# AT32F405 register map
Vendor: Keil; Series: AT32F405; File version: 1.0
CPU: CM4 r0p1, little endian, no MPU, FPU, 4 interrupt priority bits
Registers are 32-bit, read-write, reset 0x0 unless marked. A register's access mark holds for its fields unless they carry their own. Offsets are from the block's base; [hi:lo] are bit positions; {n}, {i} and the like mark numbered series.

## PWC — Power control
Base 0x40007000
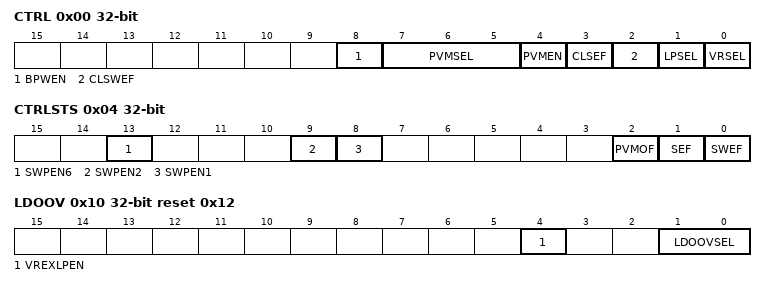
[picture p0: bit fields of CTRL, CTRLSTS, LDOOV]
0x00 CTRL — Power control register (PWC_CTRL)
  [8] BPWEN — Battery powered domain write enable
  [7:5] PVMSEL — Power voltage monitoring boundary select
  [4] PVMEN — Power voltage monitoring enable
  [3] CLSEF — Clear SEF flag
  [2] CLSWEF — Clear SWEF flag
  [1] LPSEL — Low power mode select when Cortex-M4F sleepdeep
  [0] VRSEL — Voltage regulator state select when deepsleep mode
0x04 CTRLSTS — Power control and status register (PWC_CTRLSTS)
  [13] SWPEN6 — Standby wake-up pin 6 enable
  [9] SWPEN2 — Standby wake-up pin 2 enable
  [8] SWPEN1 — Standby wake-up pin 1 enable
  [2] PVMOF ro — Power voltage monitoring output flag
  [1] SEF ro — Standby mode entry flag
  [0] SWEF ro — Standby wake-up event flag
0x10 LDOOV reset 0x12 — LDO output voltage register
  [4] VREXLPEN — Voltage regulator extra low power mode enable
  [1:0] LDOOVSEL — LDO output voltage select

## GPIOA — General purpose I/Os
Base 0x40020000
Same registers: GPIOB 0x40020400, GPIOC 0x40020800, GPIOD 0x40020C00, GPIOF 0x40021400
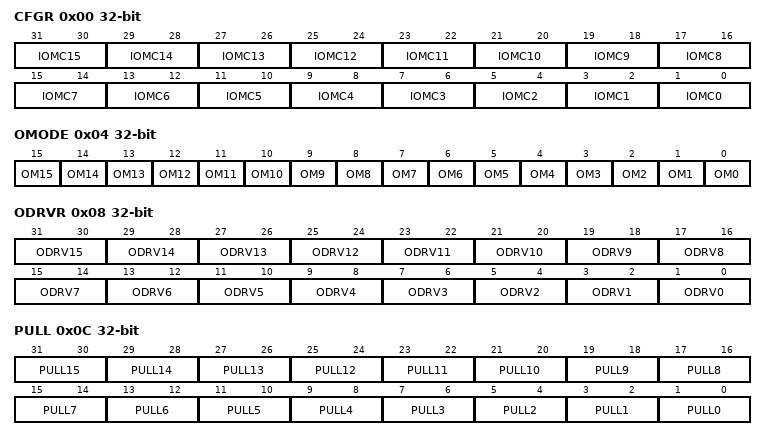
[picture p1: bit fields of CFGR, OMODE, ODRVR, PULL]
0x00 CFGR — GPIO configuration register
  [2n+1:2n] IOMC{n} (n=0..15) — GPIOx pin {n} mode configurate
    0=Input mode; 1=Output (General-purpose output mode); 2=Multiplexed function mode; 3=Analog mode
0x04 OMODE — GPIO output mode register
  [n] OM{n} (n=0..15) — GPIOx pin {n} outpu mode configurate
    0=PushPull; 1=OpenDrain
0x08 ODRVR — GPIO drive capability register
  [2n+1:2n] ODRV{n} (n=0..15) — GPIOx pin {n} output drive capability
    0=Normal sourcing/sinking strength; 1=Large sourcing/sinking strength
0x0C PULL — GPIO pull-up/pull-down register
  [2n+1:2n] PULL{n} (n=0..15) — GPIOx pin {n} pull configuration
    0=No pull-up/pull-down; 1=PullUp; 2=PullDown
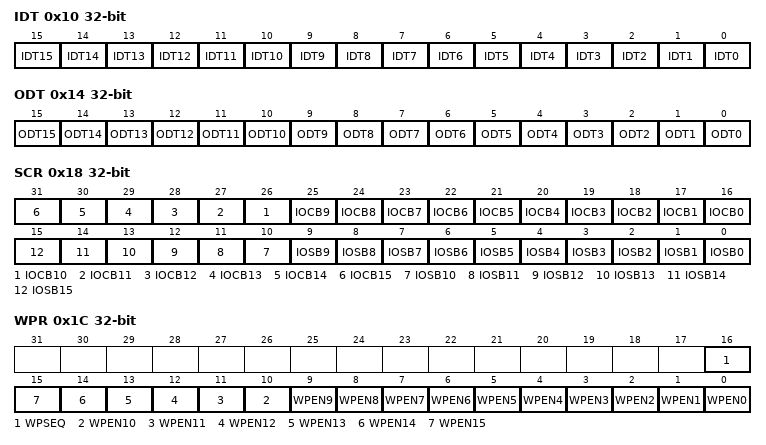
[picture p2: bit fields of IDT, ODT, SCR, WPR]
0x10 IDT ro — GPIO input data register
  [n] IDT{n} (n=0..15) — Port input data
    0=Low (Input is logic low); 1=High (Input is logic high)
0x14 ODT — GPIO output data register
  [n] ODT{n} (n=0..15) — Port output data
    on read: 0=PullDown; 1=PullUp | on write: 0=Low (Set output to logic low); 1=High (Set output to logic high)
0x18 SCR wo — Port bit set/clear register
  [n+16] IOCB{n} (n=0..15) write-1-clears — Clear bit {n}
    1=Clear the corresponding ODT bit
  [n] IOSB{n} (n=0..15) write-1-sets — Set bit {n}
    1=Set (Set the corresponding ODT bit)
0x1C WPR — Port write protect register
  [16] WPSEQ — Write protect sequence
    0=Clear; 1=Set
  [n] WPEN{n} (n=0..15) — Write protect enable {n}
    on read: 0=NotProtected (Port is not write protected); 1=Protected (Port is write protected) | on write: 0=NoProtect (No effect); 1=Protect (Write protect)
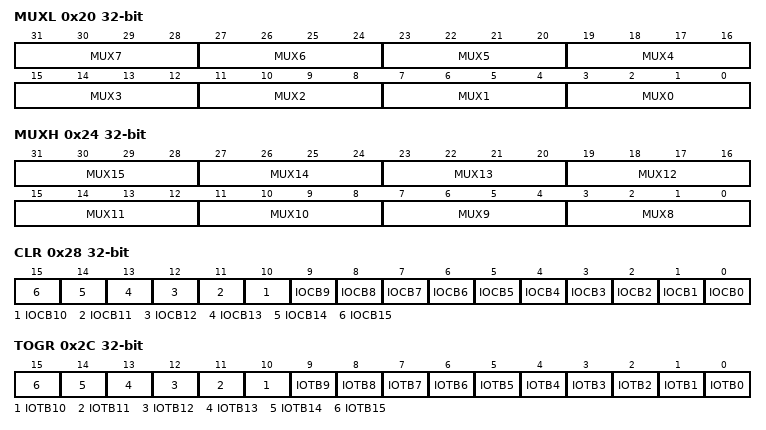
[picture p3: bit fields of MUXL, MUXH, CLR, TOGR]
0x20 MUXL — GPIO muxing function low register
  [4n+3:4n] MUX{n} (n=0..7) — GPIOx pin {n} muxing
0x24 MUXH — GPIO muxing function high register
  [4n-29:4n-32] MUX{n} (n=8..15) — GPIOx pin {n} muxing
0x28 CLR wo — GPIO bit reset register
  [n] IOCB{n} (n=0..15) write-1-clears — Clear bit {n}
    1=Clear the corresponding ODT bit
0x2C TOGR wo — GPIO bit toggle register
  [n] IOTB{n} (n=0..15) — toggle bit {n}
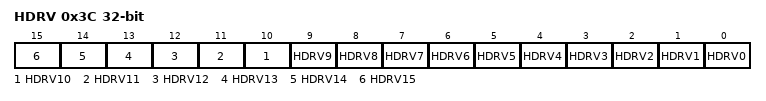
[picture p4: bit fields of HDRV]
0x3C HDRV — Huge current driver
  [n] HDRV{n} (n=0..15) — Port x driver bit y

## EXINT
Base 0x40013C00
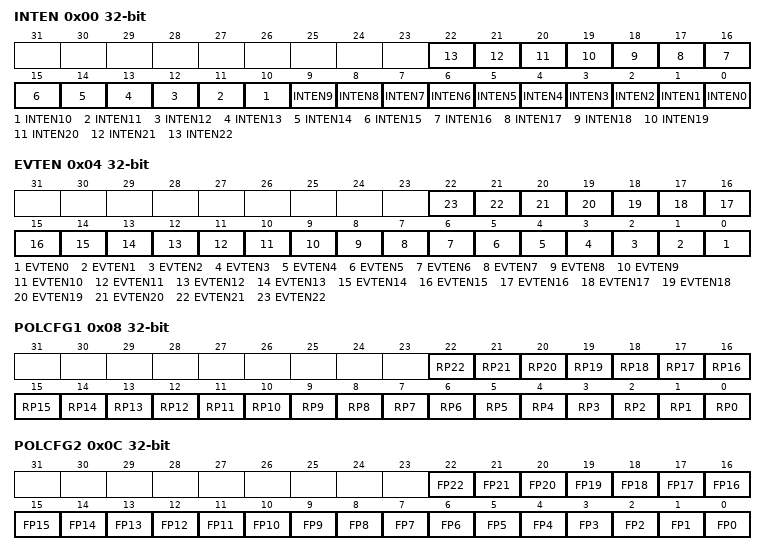
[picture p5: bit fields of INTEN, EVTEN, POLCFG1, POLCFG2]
0x00 INTEN — Interrupt enable register
  [n] INTEN{n} (n=0..22) — Interrupt enable or disable on line {n}
    on read: 0=Disabled (Interrupt request is disabled); 1=Enabled (Interrupt request is enabled) | on write: 0=Disable (Interrupt request disable); 1=Enable (Interrupt request enable)
0x04 EVTEN — Event enable register
  [n] EVTEN{n} (n=0..22) — Event enable or disable on line {n}
    on read: 0=Disabled (Event request is disabled); 1=Enabled (Event request is enabled) | on write: 0=Disable (Event request disable); 1=Enable (Event request enable)
0x08 POLCFG1 — Rising polarity configuration register
  [n] RP{n} (n=0..22) — Rising polarity configuration bit on line {n}
    on read: 0=Disabled (Rising trigger is disabled); 1=Enabled (Rising trigger is enabled) | on write: 0=Disable (Rising trigger disable); 1=Enable (Rising trigger enable)
0x0C POLCFG2 — Falling polarity configuration register
  [n] FP{n} (n=0..22) — Falling polarity configuration bit on line {n}
    on read: 0=Disabled (Falling polarity is disabled); 1=Enabled (Falling polarity is enabled) | on write: 0=Disable (Falling polarity disable); 1=Enable (Falling polarity enable)
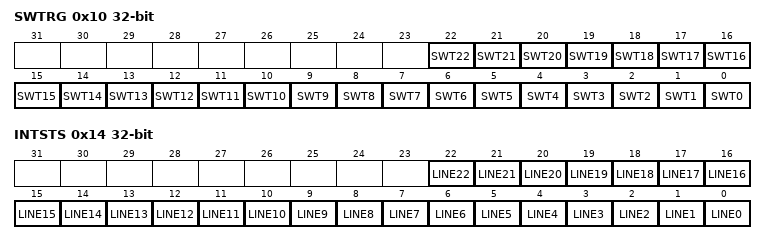
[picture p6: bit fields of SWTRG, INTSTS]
0x10 SWTRG — Software triggle register
  [n] SWT{n} (n=0..22) write-1-sets — Software trigger on line {n}
    on read: 0=NoTrigger (Default value); 1=Triggered (Software trigger generated) | on write: 1=Trigger (Generate trigger)
0x14 INTSTS — Interrupt status register
  [n] LINE{n} (n=0..22) write-1-clears — Line {n} status bit
    on read: 0=No interrupt occurred; 1=Interrupt occurred | on write: 1=Clear status flag
